# APM32F411 register map
Vendor: Geehy; File version: 2024.11.05
CPU: CM4 r1p0, little endian, 3 interrupt priority bits
Registers are 32-bit, read-write, reset 0x0 unless marked. A register's access mark holds for its fields unless they carry their own. Offsets are from the block's base; [hi:lo] are bit positions.

## UART4 — Universal synchronous asynchronous receiver transmitter
Base 0x40004C00
Same registers: UART5 0x40005000
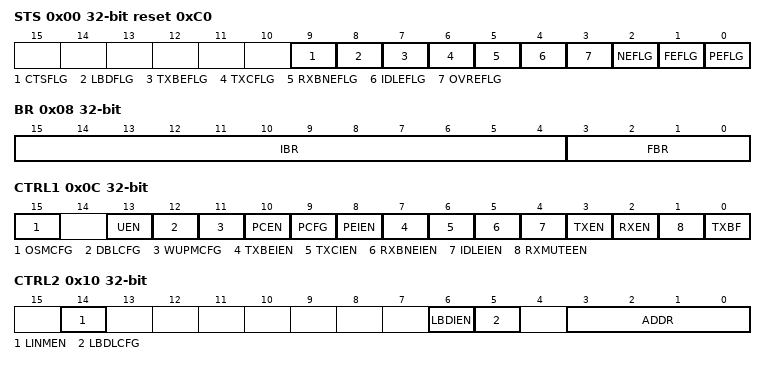
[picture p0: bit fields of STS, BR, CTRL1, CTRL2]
0x00 STS access per field reset 0xC0 — Status register
  [9] CTSFLG rw — CTS Change Flag
  [8] LBDFLG rw — LIN break detection flag
  [7] TXBEFLG ro — Transmit data register empty
  [6] TXCFLG rw — Transmission complete
  [5] RXBNEFLG rw — Read data register not empty
  [4] IDLEFLG ro — IDLE line detected
  [3] OVREFLG ro — Overrun error
  [2] NEFLG ro — Noise detected flag
  [1] FEFLG ro — Framing error
  [0] PEFLG ro — Parity error
0x04 DATA
  [8:0] DATA — Data value
0x08 BR — Baud rate register
  [15:4] IBR — mantissa of USARTDIV
  [3:0] FBR — fraction of USARTDIV
0x0C CTRL1 — Control register 1
  [15] OSMCFG — Oversampling mode
  [13] UEN — USART enable
  [12] DBLCFG — Word length
  [11] WUPMCFG — Wakeup method
  [10] PCEN — Parity control enable
  [9] PCFG — Parity selection
  [8] PEIEN — PE interrupt enable
  [7] TXBEIEN — TXE interrupt enable
  [6] TXCIEN — Transmission complete interrupt enable
  [5] RXBNEIEN — RXNE interrupt enable
  [4] IDLEIEN — IDLE interrupt enable
  [3] TXEN — Transmitter enable
  [2] RXEN — Receiver enable
  [1] RXMUTEEN — Receiver wakeup
  [0] TXBF — Send break
0x10 CTRL2 — Control register 2
  [14] LINMEN — LIN mode enable
  [6] LBDIEN — LIN break detection interrupt enable
  [5] LBDLCFG — lin break detection length
  [3:0] ADDR — Address of the USART node
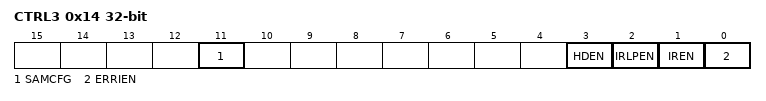
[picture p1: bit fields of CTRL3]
0x14 CTRL3 — Control register 3
  [11] SAMCFG — One sample bit method enable
  [3] HDEN — Half-duplex selection
  [2] IRLPEN — IrDA low-power
  [1] IREN — IrDA mode enable
  [0] ERRIEN — Error interrupt enable

## USART1 — Universal synchronous asynchronous receiver transmitter
Base 0x40011000
Same registers: USART2 0x40004400, USART3 0x40004800, USART6 0x40011400
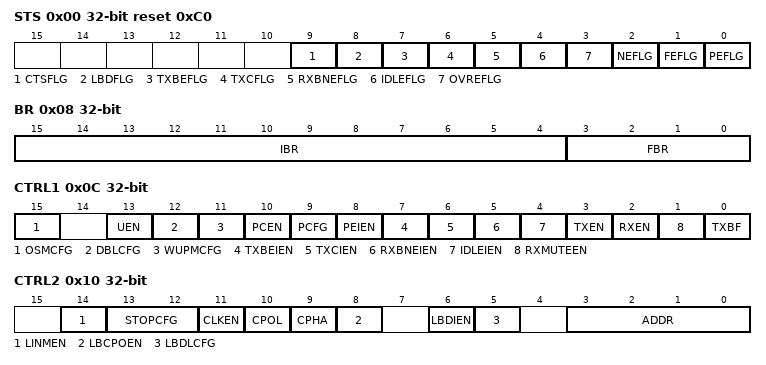
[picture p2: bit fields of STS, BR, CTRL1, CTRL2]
0x00 STS access per field reset 0xC0 — Status register
  [9] CTSFLG rw — CTS flag
  [8] LBDFLG rw — LIN break detection flag
  [7] TXBEFLG ro — Transmit data register empty
  [6] TXCFLG rw — Transmission complete
  [5] RXBNEFLG rw — Read data register not empty
  [4] IDLEFLG ro — IDLE line detected
  [3] OVREFLG ro — Overrun error
  [2] NEFLG ro — Noise detected flag
  [1] FEFLG ro — Framing error
  [0] PEFLG ro — Parity error
0x04 DATA
  [8:0] DATA — Data value
0x08 BR — Baud rate register
  [15:4] IBR — mantissa of USARTDIV
  [3:0] FBR — fraction of USARTDIV
0x0C CTRL1 — Control register 1
  [15] OSMCFG — Oversampling mode
  [13] UEN — USART enable
  [12] DBLCFG — Word length
  [11] WUPMCFG — Wakeup method
  [10] PCEN — Parity control enable
  [9] PCFG — Parity selection
  [8] PEIEN — Parity Error Interrupt Enable
  [7] TXBEIEN — Transmit Buffer Empty Interrupt Enable
  [6] TXCIEN — Transmission complete interrupt enable
  [5] RXBNEIEN — RXNE interrupt enable
  [4] IDLEIEN — IDLE interrupt enable
  [3] TXEN — Transmitter enable
  [2] RXEN — Receiver enable
  [1] RXMUTEEN — Receiver wakeup
  [0] TXBF — Send break
0x10 CTRL2 — Control register 2
  [14] LINMEN — LIN mode enable
  [13:12] STOPCFG — STOP bits
  [11] CLKEN — Clock enable
  [10] CPOL — Clock polarity
  [9] CPHA — Clock phase
  [8] LBCPOEN — Last bit clock pulse
  [6] LBDIEN — LIN break detection interrupt enable
  [5] LBDLCFG — lin break detection length
  [3:0] ADDR — Address of the USART node
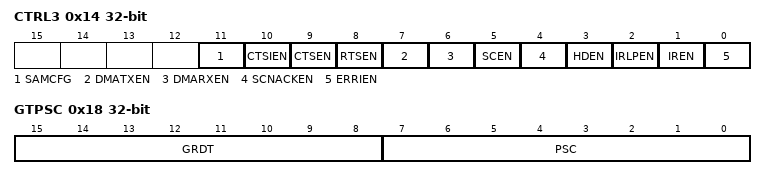
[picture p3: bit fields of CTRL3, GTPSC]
0x14 CTRL3 — Control register 3
  [11] SAMCFG — One sample bit method enable
  [10] CTSIEN — CTS interrupt enable
  [9] CTSEN — CTS enable
  [8] RTSEN — RTS enable
  [7] DMATXEN — DMA enable transmitter
  [6] DMARXEN — DMA enable receiver
  [5] SCEN — Smartcard mode enable
  [4] SCNACKEN — Smartcard NACK enable
  [3] HDEN — Half-duplex selection
  [2] IRLPEN — IrDA low-power
  [1] IREN — IrDA mode enable
  [0] ERRIEN — Error interrupt enable
0x18 GTPSC — Guard time and prescaler register
  [15:8] GRDT — Guard time value
  [7:0] PSC — Prescaler value
